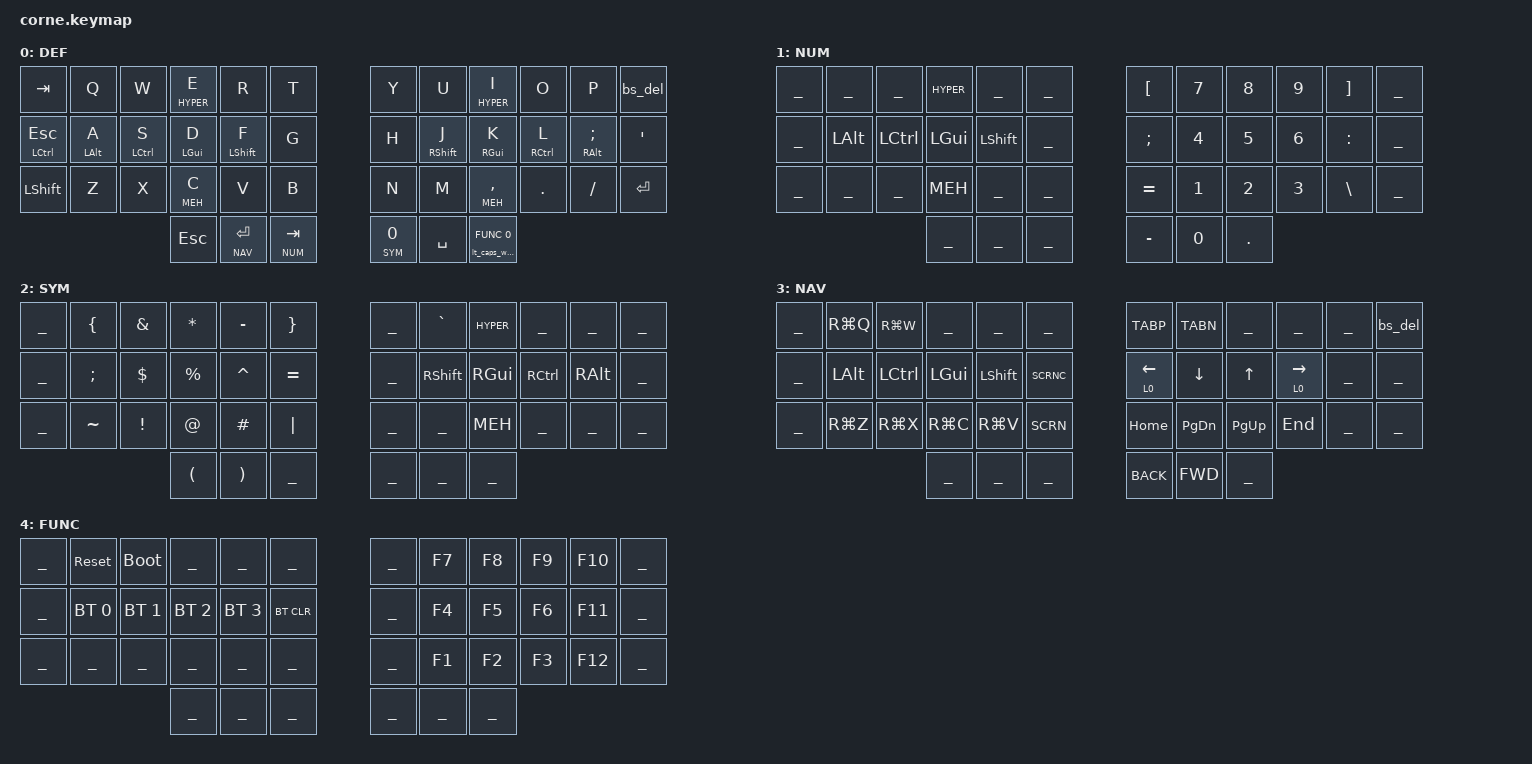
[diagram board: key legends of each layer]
/*                KEY POSITIONS

    ╭────────────────────────╮ ╭────────────────────────╮
    │ 0   1   2   3   4   5  │ │ 6   7   8   9   10  11 │
    │ 12  13  14  15  16  17 │ │ 18  19  20  21  22  23 │
    │ 24  25  26  27  28  29 │ │ 30  31  32  33  34  35 │
    ╰───────────╮ 36  37  38 │ │ 39  40  41 ╭───────────╯
                ╰────────────╯ ╰────────────╯
*/

// ZMK includes
#include <behaviors.dtsi>
#include <dt-bindings/zmk/keys.h>
#include <dt-bindings/zmk/bt.h>
// #include <dt-bindings/zmk/mouse.h>

// LAYERS
#define DEF     0
#define NUM     1
#define SYM     2
#define NAV     3
#define FUNC    4
// #define MSE     5

// ZR Includes
#include "includes/custom_keycodes.dtsi"
#include "includes/settings.dtsi"
#include "includes/combos.dtsi"
#include "includes/behaviours.dtsi"

/ {

    keymap {
        compatible = "zmk,keymap";

        default_layer {
            label = "DEF";
            bindings = <
//    ╭─────────────┬─────────────┬─────────────┬───────────────┬───────────────┬────────────────╮    ╭─────────────────┬────────────────┬──────────────┬────────────────┬────────────────┬──────────────╮
//    │     TAB     │      Q      │      W      │   E [HYPER]   │      R        │        T       │    │       Y         │      U         │   I [HYPER]  │        O       │        P       │    BS_DEL    │
//    ├─────────────┼─────────────┼─────────────┼───────────────┼───────────────┼────────────────┤    ├─────────────────┼────────────────┼──────────────┼────────────────┼────────────────┼──────────────┤
//    │ ESC [LCTRL] │  A [LALT]   │  S [LCTRL]  │   D [LGUI]    │   F [LSHFT]   │        G       │    │       H         │    J [RSHFT]   │   K [RGUI]   │   L [RCTRL]    │   ; [RALT]     │       '      │
//    ├─────────────┼─────────────┼─────────────┼───────────────┼───────────────┼────────────────|    |─────────────────┼────────────────┼──────────────┼────────────────┼────────────────┼──────────────┤
//    │    LSHFT    │      Z      │      X      │   C [MEH]     │      V        │        B       │    │       N         │        M       │    , [MEH]   │       .        │        /       │     ENTER    │
//    ╰─────────────┴─────────────┴─────────────┼───────────────┼───────────────┼────────────────|    |─────────────────┼────────────────┼──────────────┼────────────────┴────────────────┴──────────────╯
//                                              │      ESC      │   RET [NAV]   │   TAB [NUM]    │    |   bspc [SYM]    │     SPACE      │ caps_word [FUNC] │
//                                              ╰───────────────┴───────────────┴────────────────╯    ╰─────────────────┴────────────────┴──────────────╯
    &kp TAB        &kp Q        &kp W         &hml HYPER E  &kp R           &kp T           &kp Y     &kp U           &hmr HYPER I    &kp O           &kp P           &bs_del
    &mt LCTRL ESC  &hml LALT A  &hml LCTRL S  &hml LGUI D   &hml LSHFT F    &kp G           &kp H     &hmr RSHFT J    &hmr RGUI K     &hmr RCTRL L    &hmr RALT SEMI  &kp SQT
    &kp LSHFT      &kp Z        &kp X         &hml MEH C    &kp V           &kp B           &kp N     &kp M           &hmr MEH COMMA  &kp DOT         &kp FSLH        &kp RET
                                            &kp ESC    &lt NAV RET    &lt NUM TAB         &lt_bspc SYM 0    &kp SPACE    &lt_caps_word FUNC 0
            >;
        };

        num_layer {
            label = "NUM";
            bindings = <
//    ╭──────┬──────┬──────┬──────┬──────┬──────╮    ╭──────┬──────┬──────┬──────┬──────┬──────╮
//    │      │      │      │ HYPER│      │      │    │   [  │   7  │   8  │   9  │   ]  │      │
//    ├──────┼──────┼──────┼──────┼──────┼──────┤    ├──────┼──────┼──────┼──────┼──────┼──────┤
//    │      │ LALT │ LCTRL│ LGUI │ LSHFT│      │    │   +  │   4  │   5  │   6  │   :  │      │
//    ├──────┼──────┼──────┼──────┼──────┼──────|    |──────┼──────┼──────┼──────┼──────┼──────┤
//    │      │      │      │ MEH  │      │      │    │   =  │   1  │   2  │   3  │   \  │      │
//    ╰──────┴──────┴──────┼──────┼──────┼──────|    |──────┼──────┼──────┼──────┴──────┴──────╯
//                         │      │      │      │    |   -  │   0  │   .  │
//                         ╰──────┴──────┴──────╯    ╰──────┴──────┴──────╯

    ___            ___            ___            &kp HYPER      ___            ___                &kp LBKT       &kp N7         &kp N8         &kp N9         &kp RBKT       ___
    ___            &kp LALT       &kp LCTRL      &kp LGUI       &kp LSHFT      ___                &kp SEMI       &kp N4         &kp N5         &kp N6         &kp COLON      ___
    ___            ___            ___            &kp MEH        ___            ___                &kp EQUAL      &kp N1         &kp N2         &kp N3         &kp BSLH       ___
                                                ___            ___            ___                &kp MINUS      &kp N0         &kp DOT
            >;

        };

        sym_layer {
            label = "SYM";
            bindings = <
//    ╭──────┬──────┬──────┬──────┬──────┬──────╮    ╭──────┬──────┬──────┬──────┬──────┬──────╮
//    │      │   {  │   &  │   *  │   -  │   }  │    │      │   `  │ HYPER│      │      |      |
//    ├──────┼──────┼──────┼──────┼──────┼──────┤    ├──────┼──────┼──────┼──────┼──────┼──────┤
//    │      │   ;  │   $  │   %  │   ^  │   =  │    │      │ RSHFT│ RGUI │ RCTRL│ RALT │      │
//    ├──────┼──────┼──────┼──────┼──────┼──────|    |──────┼──────┼──────┼──────┼──────┼──────┤
//    │      │   ~  │   !  │   @  │   #  │   |  │    │      │      │ MEH  │      │      │      │
//    ╰──────┴──────┴──────┼──────┼──────┼──────|    |──────┼──────┼──────┼──────┴──────┴──────╯
//                         │   (  │   )  │   _  │    |      │      │      │
//                         ╰──────┴──────┴──────╯    ╰──────┴──────┴──────╯

    ___            &kp LBRC       &kp AMPS       &kp STAR       &kp MINUS       &kp RBRC          ___      &kp GRAVE      &kp HYPER      ___            ___            ___
    ___            &kp SEMI       &kp DOLLAR     &kp PRCNT      &kp CARET      &kp EQUAL          ___      &kp RSHFT      &kp RGUI       &kp RCTRL      &kp RALT       ___
    ___            &kp TILDE      &kp EXCL       &kp AT         &kp HASH       &kp PIPE           ___      ___            &kp MEH        ___            ___            ___
                                                &kp LPAR       &kp RPAR       &kp UNDER         ___      ___            ___
            >;
        };

        nav_layer {
            label = "NAV";
            bindings = <
//    ╭──────┬──────┬──────┬──────┬──────┬──────╮    ╭──────┬──────┬──────┬──────┬──────┬──────╮
//    │      │ QUIT | CLOSE│      │      │      │    │ TABP │ TABN │      │      │      │BS_DEL│
//    ├──────┼──────┼──────┼──────┼──────┼──────┤    ├──────┼──────┼──────┼──────┼──────┼──────┤
//    │      │ LOPT | LCTRL│ LCMD │ LSHFT│ SCRNC│    │ LEFT │ DOWN │  UP  │ RIGHT│      │      |
//    ├──────┼──────┼──────┼──────┼──────┼──────|    |──────┼──────┼──────┼──────┼──────┼──────┤
//    │      │ UNDO │ CUT  │ COPY │ PASTE│ SCRN |    │ HOME │ PGDN │ PGUP │  END │      │      │
//    ╰──────┴──────┴──────┼──────┼──────┼──────|    |──────┼──────┼──────┼──────┴──────┴──────╯
//                         │      │      │      │    | BACK │ FWD  │      │
//                         ╰──────┴──────┴──────╯    ╰──────┴──────┴──────╯
    ___     &kp RG(Q)      &kp RG(W)      ___            ___            ___                &kp TABP         &kp TABN       ___            ___              ___            &bs_del
    ___     &kp LALT       &kp LCTRL      &kp LGUI       &kp LSHFT      &kp SCRNC          &mt_home 0 LEFT  &kp DOWN       &kp UP         &mt_end 0 RIGHT  ___            ___
    ___     &kp RG(Z)      &kp RG(X)      &kp RG(C)      &kp RG(V)      &kp SCRN           &kp HOME         &kp PG_DN      &kp PG_UP      &kp END          ___            ___
                                        ___            ___            ___                &kp BACK       &kp FWD        ___
            >;
        };

        func_layer {
            label = "FUNC";
            bindings = <
//    ╭──────┬──────┬──────┬──────┬──────┬──────╮    ╭──────┬──────┬──────┬──────┬──────┬──────╮
//    │      │ reset| bootl|      │      │      │    │      │  F7  │  F8  │  F9  │  F10 │      │
//    ├──────┼──────┼──────┼──────┼──────┼──────┤    ├──────┼──────┼──────┼──────┼──────┼──────┤
//    │      │ BT 0 │ BT 1 │ BT 2 │ BT 3 │BT CLR│    │      │  F4  │  F5  │  F6  │  F11 │      |
//    ├──────┼──────┼──────┼──────┼──────┼──────|    |──────┼──────┼──────┼──────┼──────┼──────┤
//    │      │      │      │      │      │      │    │      │  F1  │  F2  │  F3  │  F12 │      │
//    ╰──────┴──────┴──────┼──────┼──────┼──────|    |──────┼──────┼──────┼──────┴──────┴──────╯
//                         │      │      │      │    |      |      │      │
//                         ╰──────┴──────┴──────╯    ╰──────┴──────┴──────╯

    ___     &sys_reset    &bootloader   ___           ___            ___         ___   &kp F7   &kp F8   &kp F9   &kp F10   ___
    ___     &bt BT_SEL 0  &bt BT_SEL 1  &bt BT_SEL 2  &bt BT_SEL 3   &bt BT_CLR  ___   &kp F4   &kp F5   &kp F6   &kp F11   ___
    ___     ___           ___           ___           ___            ___         ___   &kp F1   &kp F2   &kp F3   &kp F12   ___
                                                    ___     ___     ___          ___     ___     ___
            >;
        };

//         mouse_layer {
//             label = "MSE";
//             bindings = <
// //    ╭──────┬──────┬──────┬──────┬──────┬──────╮    ╭──────┬──────┬──────┬──────┬──────┬──────╮
// //    │      │      │      │      │      │      │    │      │ MW_DN│ MW_UP│      │      │      │
// //    ├──────┼──────┼──────┼──────┼──────┼──────┤    ├──────┼──────┼──────┼──────┼──────┼──────┤
// //    │      │      │      │      │      │      │    │ M_LFT│ M_DN │ M_UP │ M_RGT│      │      |
// //    ├──────┼──────┼──────┼──────┼──────┼──────|    |──────┼──────┼──────┼──────┼──────┼──────┤
// //    │      │      │      │      │      │      │    │      │      │      │      │      │      │
// //    ╰──────┴──────┴──────┼──────┼──────┼──────|    |──────┼──────┼──────┼──────┴──────┴──────╯
// //                         |      │      |      |    | LCLK │ RCLK │      |
// //                         ╰──────┴──────┴──────╯    ╰──────┴──────┴──────╯

//     ___            ___            ___            ___            ___            ___                ___            &mwh S_DOWN    &mwh S_UP      ___            ___            ___
//     ___            &kp LALT       &kp LCTRL      &kp LGUI       &kp LSHFT      ___                &mmv M_LEFT    &mmv M_DOWN    &mmv M_UP      &mmv M_RIGHT   ___            ___
//     ___            ___            ___            ___            ___            ___         ___            ___            ___            ___            ___            ___
//                                                 ___            ___            ___                &mkp LCLK      &mkp RCLK      ___
//             >;
//         };
    };
};

// blank layout
//    ╭──────┬──────┬──────┬──────┬──────┬──────╮    ╭──────┬──────┬──────┬──────┬──────┬──────╮
//    │      │      │      │      │      │      │    │      │      │      │      │      │      │
//    ├──────┼──────┼──────┼──────┼──────┼──────┤    ├──────┼──────┼──────┼──────┼──────┼──────┤
//    │      │      │      │      │      │      │    │      │      │      │      │      │      │
//    ├──────┼──────┼──────┼──────┼──────┼──────|    |──────┼──────┼──────┼──────┼──────┼──────┤
//    │      │      │      │      │      │      │    │      │      │      │      │      │      │
//    ╰──────┴──────┴──────┼──────┼──────┼──────|    |──────┼──────┼──────┼──────┴──────┴──────╯
//                         │      │      │      │    |      │      │      │
//                         ╰──────┴──────┴──────╯    ╰──────┴──────┴──────╯
